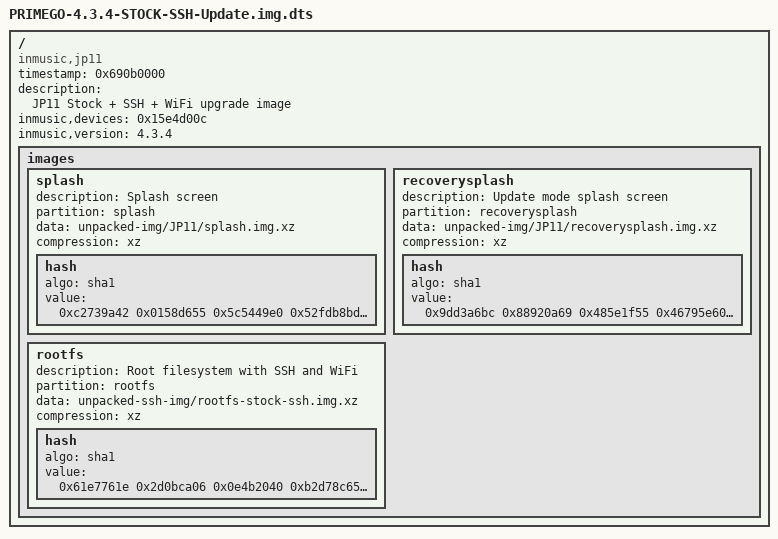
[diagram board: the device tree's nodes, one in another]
/dts-v1/;
/ {
	timestamp = <0x690b0000>;
	description = "JP11 Stock + SSH + WiFi upgrade image";
	compatible = "inmusic,jp11";
	inmusic,devices = <0x15e4d00c>;
	inmusic,version = "4.3.4";
	images {
		splash {
			description = "Splash screen";
			partition = "splash";
			data = /incbin/("unpacked-img/JP11/splash.img.xz");
			compression = "xz";
			hash { algo = "sha1"; value = <0xc2739a42 0x0158d655 0x5c5449e0 0x52fdb8bd 0x6292229f>; };
		};
		recoverysplash {
			description = "Update mode splash screen";
			partition = "recoverysplash";
			data = /incbin/("unpacked-img/JP11/recoverysplash.img.xz");
			compression = "xz";
			hash { algo = "sha1"; value = <0x9dd3a6bc 0x88920a69 0x485e1f55 0x46795e60 0xdda0ae27>; };
		};
		rootfs {
			description = "Root filesystem with SSH and WiFi";
			partition = "rootfs";
			data = /incbin/("unpacked-ssh-img/rootfs-stock-ssh.img.xz");
			compression = "xz";
			hash { algo = "sha1"; value = <0x61e7761e 0x2d0bca06 0x0e4b2040 0xb2d78c65 0xa68259d3>; };
		};
	};
};
